# Port_B_2 register map
Vendor: Texas Instruments
Peripheral module from a debugger description file (folder msp430).
Registers are 16-bit, read-write, reset 0x0 unless marked. A register's access mark holds for its fields unless they carry their own. Offsets are as the file gives them; lines under a group give offsets from that group; [hi:lo] are bit positions; {n}, {i} and the like mark numbered series; 'fields as' and 'values as' point back to an identical list; <NAME> marks a mode.

## Port_B
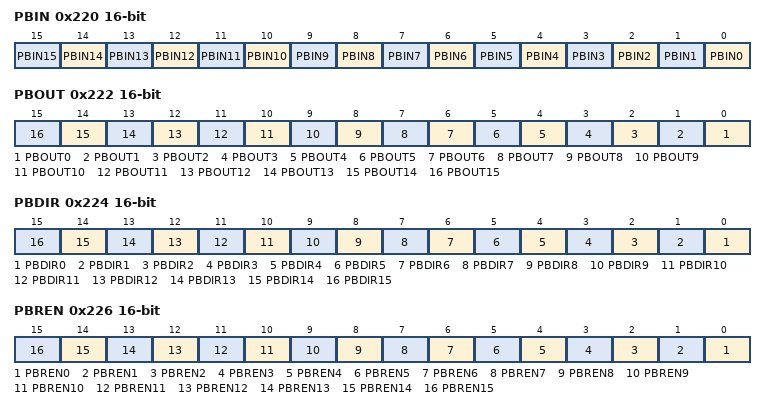
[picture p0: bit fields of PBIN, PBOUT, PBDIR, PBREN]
0x220 PBIN — Port B Input
  [n] PBIN{n} (n=0..15)
0x222 PBOUT — Port B Output
  [n] PBOUT{n} (n=0..15)
0x224 PBDIR — Port B Direction
  [n] PBDIR{n} (n=0..15)
0x226 PBREN — Port B Resistor Enable
  [n] PBREN{n} (n=0..15)
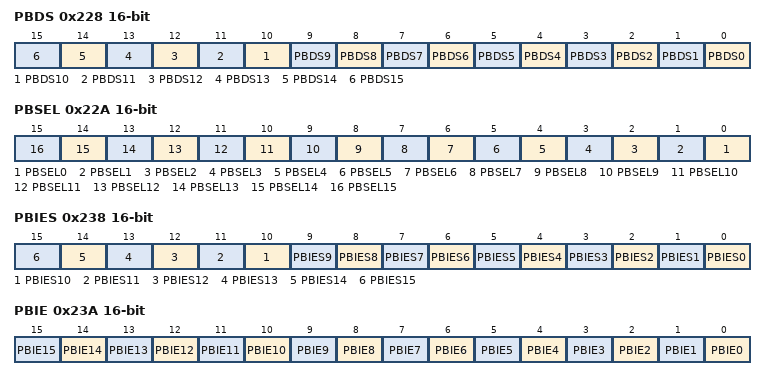
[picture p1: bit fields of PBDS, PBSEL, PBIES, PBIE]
0x228 PBDS — Port B Drive Strenght
  [n] PBDS{n} (n=0..15)
0x22A PBSEL — Port B Selection
  [n] PBSEL{n} (n=0..15)
0x238 PBIES — Port B Interrupt Edge Select
  [n] PBIES{n} (n=0..15)
0x23A PBIE — Port B Interrupt Enable
  [n] PBIE{n} (n=0..15)
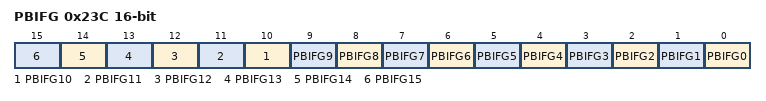
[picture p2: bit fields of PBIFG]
0x23C PBIFG — Port B Interrupt Flag
  [n] PBIFG{n} (n=0..15)
